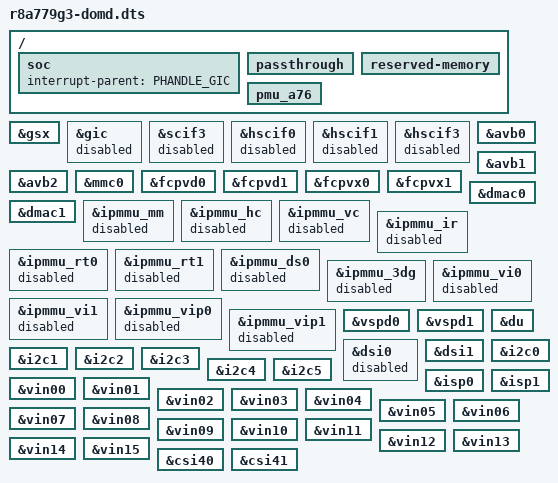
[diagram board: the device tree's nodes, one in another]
/*
 * The device tree compiler (DTC) is allocating the phandle from 1 to
 * onwards. Reserve a high value for the GIC phandle.
 */
#define PHANDLE_GIC (65000)
#define PHANDLE_ITS (64999)

/ {
	soc {
		/* This must point to Xen interrupt-parent. */
		interrupt-parent = <PHANDLE_GIC>;
	};

	passthrough {
	};

	reserved-memory {
		#address-cells = <2>;
		#size-cells = <2>;
		ranges;
	};
	/*
	 * When creating DT for the guest domain Xen inserts only dummy CPU nodes.
	 * And the number of these inserted CPU nodes is equal to the number of
	 * vCPUs assigned to this domain. All CPU properties which original DT has,
	 * such as OPP, clock, regulator, etc are not passed to the guest’s DT.
	 *
	 * Example of guest vCPU node:
	 *
	 * cpu@0 {
	 *     device_type = "cpu";
	 *     compatible = "arm,armv8";
	 *     enable-method = "psci";
	 *     reg = <0x0>;
	 * };
	 *
	 * This results in the fact that all features expecting a57_x or a53_x
	 * CPU nodes to be present get broken. This is why we have to explicitly
	 * remove the following.
	 */
	/*
	 * Remove interrupts-extended node from guest domain
	 * as it can not be shared by Xen.
	 */
	pmu_a76 {
		/delete-property/interrupts-extended;
	};

};

/ {
	/delete-node/ cmem;
//
// 	reserved-memory {
// 		linux,cma@80000000 {
// 			compatible = "shared-dma-pool";
// 			reusable;
// 			reg = <0x00000000 0x90000000 0x0 0x30000000>;
// 			//        0x0000000040000000-0x00000000bfffffff
// 			linux,cma-default;
// 		};
// 	};
};

&gsx {
	status = "okay";
};

&gic {
	compatible = "";
	status = "disabled";
};

/* Xen serial consoles */
&scif3	{
	status = "disabled";
};

&hscif0	{
	status = "disabled";
};
&hscif1	{
	status = "disabled";
};
&hscif3	{
	status = "disabled";
};

&avb0 {
	/delete-property/iommus;
};

&avb1 {
	/delete-property/iommus;
};

&avb2 {
	/delete-property/iommus;
};

&mmc0 {
	/delete-property/iommus;
};

&fcpvd0 {
	/delete-property/iommus;
};

&fcpvd1 {
	/delete-property/iommus;
};

&fcpvx0 {
	/delete-property/iommus;
};

&fcpvx1 {
	/delete-property/iommus;
};

&dmac0 {
	/delete-property/iommus;
};

&dmac1 {
	/delete-property/iommus;
};

//&rt_dmac0  {
//	/delete-property/iommus;
//};
//
//&rt_dmac1  {
//	/delete-property/iommus;
//};
//
//&rt_dmac2  {
//	/delete-property/iommus;
//};
//
//&rt_dmac3  {
//	/delete-property/iommus;
//};

&ipmmu_mm {
	status = "disabled";
};
&ipmmu_hc {
	status = "disabled";
};
&ipmmu_vc {
	status = "disabled";
};
&ipmmu_ir {
	status = "disabled";
};

&ipmmu_rt0 {
	status = "disabled";
};
&ipmmu_rt1 {
	status = "disabled";
};
&ipmmu_ds0{
	status = "disabled";
};
&ipmmu_3dg{
	status = "disabled";
};
&ipmmu_vi0{
	status = "disabled";
};
&ipmmu_vi1{
	status = "disabled";
};
&ipmmu_vip0{
	status = "disabled";
};
&ipmmu_vip1{
	status = "disabled";
};


&vspd0 {
	status = "okay";
};

&vspd1 {
	status = "okay";
};

&du {
	status = "okay";
};

//&dsc {
//	status = "disabled";
//};

&dsi0 {
	status = "disabled";
};

&dsi1 {
	status = "okay";
};

&i2c0 {
	status = "okay";
};

&i2c1 {
	status = "okay";
};

&i2c2 {
	status = "okay";
};

&i2c3 {
	status = "okay";
};

&i2c4 {
	status = "okay";
};

&i2c5 {
	status = "okay";
};

&isp0 {
	status = "okay";
};

&isp1 {
	status = "okay";
};

&vin00          { status = "okay";};
&vin01          { status = "okay";};
&vin02          { status = "okay";};
&vin03          { status = "okay";};
&vin03          { status = "okay";};
&vin04          { status = "okay";};
&vin05          { status = "okay";};
&vin06          { status = "okay";};
&vin07          { status = "okay";};
&vin08          { status = "okay";};
&vin09          { status = "okay";};
&vin10          { status = "okay";};
&vin11          { status = "okay";};
&vin12          { status = "okay";};
&vin13          { status = "okay";};
&vin14          { status = "okay";};
&vin15          { status = "okay";};
&csi40		   	{ status = "okay";};
&csi41		   	{ status = "okay";};

//&gmsl0 {
//	status = "okay";
//};
//
//&gmsl1 {
//	status = "okay";
//};
